# CY8C5868AXI_LP035 register map
File version: 0.1
CY8C58LP
Registers are 8-bit, read-write, no defined reset value unless marked. A register's access mark holds for its fields unless they carry their own. Offsets are from the block's base; lines under a group give offsets from that group; [hi:lo] are bit positions; {n}, {i} and the like mark numbered series; 'fields as' and 'values as' point back to an identical list; <NAME> marks a mode.

## Memory map
0x00000000 UART_1 — UART
0x40006575 Control_Reg_1

## UART_1 — UART
Base 0x00000000
0x40006429 RX_UART_1_RX_ADDRESS1 — RX Address1 Register
0x40006439 RX_UART_1_RX_ADDRESS2 — RX Address2 Register
0x40006449 RX_UART_1_RX_DATA — RX Data Register
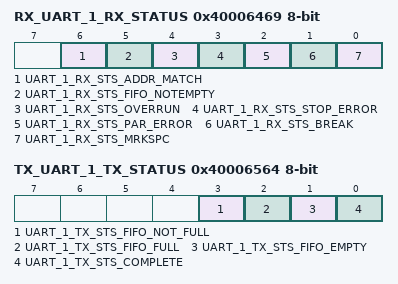
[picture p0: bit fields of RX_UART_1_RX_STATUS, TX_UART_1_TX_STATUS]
0x40006469 RX_UART_1_RX_STATUS — RX status register
  [6] UART_1_RX_STS_ADDR_MATCH ro, [5] UART_1_RX_STS_FIFO_NOTEMPTY ro, [4] UART_1_RX_STS_OVERRUN ro, [3] UART_1_RX_STS_STOP_ERROR ro, [2] UART_1_RX_STS_PAR_ERROR ro, [1] UART_1_RX_STS_BREAK ro, [0] UART_1_RX_STS_MRKSPC ro
0x40006544 TX_UART_1_TX_DATA — TX Data Register
0x40006564 TX_UART_1_TX_STATUS — TX status register
  [3] UART_1_TX_STS_FIFO_NOT_FULL ro, [2] UART_1_TX_STS_FIFO_FULL ro, [1] UART_1_TX_STS_FIFO_EMPTY ro, [0] UART_1_TX_STS_COMPLETE ro

## Control_Reg_1
Base 0x40006575
0x00 Control_Reg_1_CONTROL_REG
